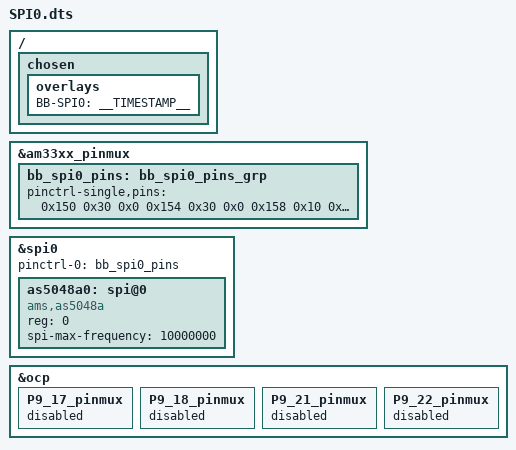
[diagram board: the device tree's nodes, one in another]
/dts-v1/;
/plugin/;

/{
	fragment@0 {
		target-path="/";
		__overlay__ {
			chosen {
				overlays {
					BB-SPI0 = "__TIMESTAMP__";
				};
			};
		};
	};

	fragment@1 {
		target = <&am33xx_pinmux>;
		__overlay__ {
			bb_spi0_pins: bb_spi0_pins_grp {
				pinctrl-single,pins = <
					0x150 0x30 0x0
					0x154 0x30 0x0
					0x158 0x10 0x0
					0x15C 0x10 0x0
				>;
			};
		};
	};

	fragment@2 {
		target = <&spi0>;
		__overlay__ {
			#address-cells = <1>;
			#size-cells = <0>;
			status = "okay";
			pinctrl-names = "default";
			pinctrl-0 = <&bb_spi0_pins>;

			as5048a0: spi@0 {
				compatible = "ams,as5048a";
				reg = <0>;
				/* 클럭 상한선만 지정. 실제 사용 클럭은 드라이버가 spi->max_speed_hz로 결정 */
				spi-max-frequency = <10000000>;
			};
		};
	};

	fragment@3 {
		target = <&ocp>;
		__overlay__ {
			P9_17_pinmux { status = "disabled"; };
			P9_18_pinmux { status = "disabled"; };
			P9_21_pinmux { status = "disabled"; };
			P9_22_pinmux { status = "disabled"; };
		};
	};
};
